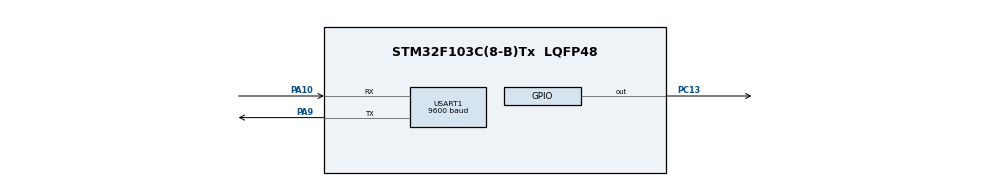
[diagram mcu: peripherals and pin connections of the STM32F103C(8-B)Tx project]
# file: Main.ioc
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Mcu.Family=STM32F1
Mcu.Name=STM32F103C(8-B)Tx
Mcu.Package=LQFP48
NVIC.PriorityGroup=NVIC_PRIORITYGROUP_4
NVIC.RTC_IRQn=true\:0\:0\:false\:false\:true\:true\:true\:true
PA10.Mode=Asynchronous
PA10.Signal=USART1_RX
PA13.Mode=JTAG_4_pins
PA13.Signal=SYS_JTMS-SWDIO
PA14.Mode=JTAG_4_pins
PA14.Signal=SYS_JTCK-SWCLK
PA15.Mode=JTAG_4_pins
PA15.Signal=SYS_JTDI
PA9.Mode=Asynchronous
PA9.Signal=USART1_TX
PB3.Mode=JTAG_4_pins
PB3.Signal=SYS_JTDO-TRACESWO
PC13-TAMPER-RTC.Signal=GPIO_Output
PC14-OSC32_IN.Mode=LSE-External-Oscillator
PC14-OSC32_IN.Signal=RCC_OSC32_IN
PC15-OSC32_OUT.Mode=LSE-External-Oscillator
PC15-OSC32_OUT.Signal=RCC_OSC32_OUT
ProjectManager.HeapSize=0x200
ProjectManager.StackSize=0x400
ProjectManager.TargetToolchain=MDK-ARM V5.32
RCC.AHBFreq_Value=8000000
RCC.APB1Freq_Value=8000000
RCC.APB1TimFreq_Value=8000000
RCC.APB2Freq_Value=8000000
RCC.APB2TimFreq_Value=8000000
RCC.HCLKFreq_Value=8000000
RCC.PLLMUL=RCC_PLL_MUL9
RCC.RTCClockSelection=RCC_RTCCLKSOURCE_LSE
RCC.SYSCLKFreq_VALUE=8000000
RCC.USBFreq_Value=36000000
RTC.AutoPrediv=RTC_AUTO_1_SECOND
RTC.Format=RTC_FORMAT_BIN
RTC.OutPut=RTC_OUTPUTSOURCE_NONE
USART1.BaudRate=9600
USART1.VirtualMode=VM_ASYNC
VP_RTC_No_RTC_Output.Mode=RTC_OUT_NO
VP_RTC_VS_RTC_Activate.Mode=RTC_Enabled
board=custom

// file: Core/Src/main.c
/* USER CODE BEGIN Header */
/**
  ******************************************************************************
  * @file           : main.c
  * @brief          : Main program body
  ******************************************************************************
  * @attention
  *
  * Copyright (c) 2026 STMicroelectronics.
  * All rights reserved.
  *
  * This software is licensed under terms that can be found in the LICENSE file
  * in the root directory of this software component.
  * If no LICENSE file comes with this software, it is provided AS-IS.
  *
  ******************************************************************************
  */
/* USER CODE END Header */
#include "main.h"

/* USER CODE BEGIN PV */
volatile uint8_t rtc_sec_flag = 0;
volatile uint8_t rtc_alarm_flag = 0;
volatile uint32_t systick_ms = 0;
/* USER CODE END PV */

void SystemClock_Config(void);
static void MX_GPIO_Init(void);
static void MX_RTC_Init(void);
static void MX_USART1_UART_Init(void);
/* USER CODE BEGIN PFP */
static void LL_USART_TransmitString(USART_TypeDef *USARTx, const char *str);
/* USER CODE END PFP */

int main(void)
{

  /* USER CODE BEGIN 1 */
  uint32_t led_on_tick = 0;
  /* USER CODE END 1 */

  /* MCU Configuration--------------------------------------------------------*/

  /* Reset of all peripherals, Initializes the Flash interface and the Systick. */
  LL_APB2_GRP1_EnableClock(LL_APB2_GRP1_PERIPH_AFIO);
  LL_APB1_GRP1_EnableClock(LL_APB1_GRP1_PERIPH_PWR);

  /* System interrupt init*/
  NVIC_SetPriorityGrouping(NVIC_PRIORITYGROUP_4);

  /** NONJTRST: Full SWJ (JTAG-DP + SW-DP) but without NJTRST
  */
  LL_GPIO_AF_Remap_SWJ_NONJTRST();

  /* Configure the system clock */
  SystemClock_Config();

  /* Initialize all configured peripherals */
  MX_GPIO_Init();
  MX_RTC_Init();
  MX_USART1_UART_Init();
  /* USER CODE BEGIN 2 */
	if (LL_RTC_EnterInitMode(RTC) == SUCCESS){
		LL_RTC_SetAsynchPrescaler(RTC, 0x00007FFFU);
		LL_RTC_TIME_Set(RTC, 0);
		LL_RTC_ALARM_Set(RTC, 10);

		LL_RTC_ExitInitMode(RTC);

		LL_RTC_EnableIT_SEC(RTC);
		LL_RTC_EnableIT_ALR(RTC);

		LL_USART_TransmitString(USART1, "RTC Config: OK\r");
	}
	else{
		LL_USART_TransmitString(USART1, "RTC Config: ERROR \r");
	}

	LL_SYSTICK_EnableIT();
  /* USER CODE END 2 */

  /* Infinite loop */
  while (1){

    /* USER CODE BEGIN 3 */
		if(rtc_sec_flag == 1){
			rtc_sec_flag = 0;
      LL_GPIO_ResetOutputPin(GPIOC, LL_GPIO_PIN_13);
      led_on_tick = systick_ms;
    }
    if(led_on_tick > 0){
      if((int32_t)(systick_ms - led_on_tick) >= 100){
        LL_GPIO_SetOutputPin(GPIOC, LL_GPIO_PIN_13);
        led_on_tick = 0;
      }
    }

    if(rtc_alarm_flag == 1){
			rtc_alarm_flag = 0;
      uint32_t cnt1 = 0, cnt2 = 0;
      do{
        cnt1 = LL_RTC_TIME_Get(RTC);
        cnt2 = LL_RTC_TIME_Get(RTC);
      } while(cnt1 != cnt2);

      LL_RTC_EnterInitMode(RTC);
      LL_RTC_ALARM_Set(RTC, cnt2 + 10);
      LL_RTC_ExitInitMode(RTC);

      LL_USART_TransmitString(USART1, "RTC ALARM !!!\r");
    }
  }
  /* USER CODE END 3 */
}

void SystemClock_Config(void)
{
  LL_FLASH_SetLatency(LL_FLASH_LATENCY_0);
  while(LL_FLASH_GetLatency()!= LL_FLASH_LATENCY_0)
  {
  }
  LL_RCC_HSI_SetCalibTrimming(16);
  LL_RCC_HSI_Enable();

   /* Wait till HSI is ready */
  while(LL_RCC_HSI_IsReady() != 1)
  {

  }
  LL_PWR_EnableBkUpAccess();
  if(LL_RCC_GetRTCClockSource() != LL_RCC_RTC_CLKSOURCE_LSE)
  {
    LL_RCC_ForceBackupDomainReset();
    LL_RCC_ReleaseBackupDomainReset();
  }
  LL_RCC_LSE_Enable();

   /* Wait till LSE is ready */
  while(LL_RCC_LSE_IsReady() != 1)
  {

  }
  if(LL_RCC_GetRTCClockSource() != LL_RCC_RTC_CLKSOURCE_LSE)
  {
    LL_RCC_SetRTCClockSource(LL_RCC_RTC_CLKSOURCE_LSE);
  }
  LL_RCC_EnableRTC();
  LL_RCC_SetAHBPrescaler(LL_RCC_SYSCLK_DIV_1);
  LL_RCC_SetAPB1Prescaler(LL_RCC_APB1_DIV_1);
  LL_RCC_SetAPB2Prescaler(LL_RCC_APB2_DIV_1);
  LL_RCC_SetSysClkSource(LL_RCC_SYS_CLKSOURCE_HSI);

   /* Wait till System clock is ready */
  while(LL_RCC_GetSysClkSource() != LL_RCC_SYS_CLKSOURCE_STATUS_HSI)
  {

  }
  LL_Init1msTick(8000000);
  LL_SetSystemCoreClock(8000000);
}

static void MX_RTC_Init(void)
{

  LL_RTC_InitTypeDef RTC_InitStruct = {0};
  LL_RTC_TimeTypeDef RTC_TimeStruct = {0};

    LL_PWR_EnableBkUpAccess();
    /* Enable BKP CLK enable for backup registers */
    LL_APB1_GRP1_EnableClock(LL_APB1_GRP1_PERIPH_BKP);
  /* Peripheral clock enable */
  LL_RCC_EnableRTC();

  /* RTC interrupt Init */
  NVIC_SetPriority(RTC_IRQn, NVIC_EncodePriority(NVIC_GetPriorityGrouping(),0, 0));
  NVIC_EnableIRQ(RTC_IRQn);

  /** Initialize RTC and set the Time and Date
  */
  RTC_InitStruct.AsynchPrescaler = 0xFFFFFFFFU;
  LL_RTC_Init(RTC, &RTC_InitStruct);
  LL_RTC_SetAsynchPrescaler(RTC, 0xFFFFFFFFU);

  /** Initialize RTC and set the Time and Date
  */
  RTC_TimeStruct.Hours = 0;
  RTC_TimeStruct.Minutes = 0;
  RTC_TimeStruct.Seconds = 0;
  LL_RTC_TIME_Init(RTC, LL_RTC_FORMAT_BIN, &RTC_TimeStruct);

  /** Enable the Alarm A
  */
  LL_RTC_EnableIT_ALR(RTC);

}

static void MX_USART1_UART_Init(void)
{

  LL_USART_InitTypeDef USART_InitStruct = {0};

  LL_GPIO_InitTypeDef GPIO_InitStruct = {0};

  /* Peripheral clock enable */
  LL_APB2_GRP1_EnableClock(LL_APB2_GRP1_PERIPH_USART1);

  LL_APB2_GRP1_EnableClock(LL_APB2_GRP1_PERIPH_GPIOA);
  /**USART1 GPIO Configuration
  PA9   ------> USART1_TX
  PA10   ------> USART1_RX
  */
  GPIO_InitStruct.Pin = LL_GPIO_PIN_9;
  GPIO_InitStruct.Mode = LL_GPIO_MODE_ALTERNATE;
  GPIO_InitStruct.Speed = LL_GPIO_SPEED_FREQ_HIGH;
  GPIO_InitStruct.OutputType = LL_GPIO_OUTPUT_PUSHPULL;
  LL_GPIO_Init(GPIOA, &GPIO_InitStruct);

  GPIO_InitStruct.Pin = LL_GPIO_PIN_10;
  GPIO_InitStruct.Mode = LL_GPIO_MODE_FLOATING;
  LL_GPIO_Init(GPIOA, &GPIO_InitStruct);

  USART_InitStruct.BaudRate = 9600;
  USART_InitStruct.DataWidth = LL_USART_DATAWIDTH_8B;
  USART_InitStruct.StopBits = LL_USART_STOPBITS_1;
  USART_InitStruct.Parity = LL_USART_PARITY_NONE;
  USART_InitStruct.TransferDirection = LL_USART_DIRECTION_TX_RX;
  USART_InitStruct.HardwareFlowControl = LL_USART_HWCONTROL_NONE;
  USART_InitStruct.OverSampling = LL_USART_OVERSAMPLING_16;
  LL_USART_Init(USART1, &USART_InitStruct);
  LL_USART_ConfigAsyncMode(USART1);
  LL_USART_Enable(USART1);

}

static void MX_GPIO_Init(void)
{
  LL_GPIO_InitTypeDef GPIO_InitStruct = {0};

  /* GPIO Ports Clock Enable */
  LL_APB2_GRP1_EnableClock(LL_APB2_GRP1_PERIPH_GPIOC);
  LL_APB2_GRP1_EnableClock(LL_APB2_GRP1_PERIPH_GPIOA);
  LL_APB2_GRP1_EnableClock(LL_APB2_GRP1_PERIPH_GPIOB);

  /**/
  LL_GPIO_SetOutputPin(GPIOC, LL_GPIO_PIN_13);

  /**/
  GPIO_InitStruct.Pin = LL_GPIO_PIN_13;
  GPIO_InitStruct.Mode = LL_GPIO_MODE_OUTPUT;
  GPIO_InitStruct.Speed = LL_GPIO_SPEED_FREQ_LOW;
  GPIO_InitStruct.OutputType = LL_GPIO_OUTPUT_PUSHPULL;
  LL_GPIO_Init(GPIOC, &GPIO_InitStruct);

}

/* USER CODE BEGIN 4 */
void LL_USART_TransmitString(USART_TypeDef *USARTx, const char *str){
  while(*str != 0){
		while(LL_USART_IsActiveFlag_TXE(USARTx) != 1){}		// Transmit Data Register Empty
		LL_USART_TransmitData8(USARTx, *str);
    str++;
	}
}
/* USER CODE END 4 */

void Error_Handler(void)
{
  __disable_irq();
  while (1)
  {
  }
}
